# alb32r003x register map
Vendor: ALB; Series: ALB RT SoC
CPU: ALB XF, little endian
Registers are 32-bit, access not given, reset 0x0 unless marked. A register's access mark holds for its fields unless they carry their own. Offsets are from the block's base; [hi:lo] are bit positions; {n}, {i} and the like mark numbered series.

## ADCA
Base 0x20800100
Same registers: ADCB 0x20800300, ADCC 0x20800500
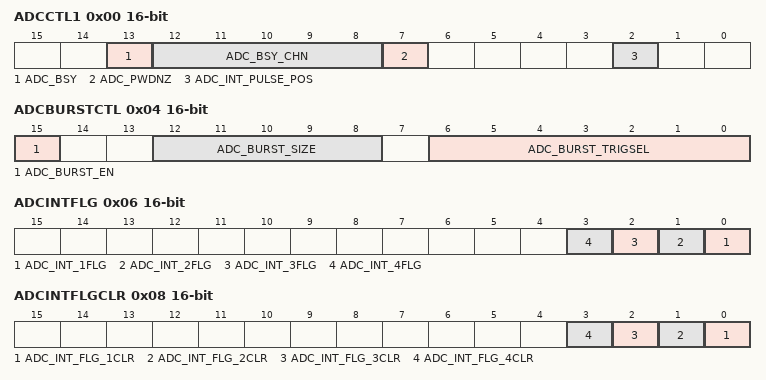
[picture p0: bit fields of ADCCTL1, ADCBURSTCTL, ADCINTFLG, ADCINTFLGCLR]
0x00 ADCCTL1 16-bit
  [13] ADC_BSY — ADC Busy. Set when ADC SOC is generated, cleared by hardware
  [12:8] ADC_BSY_CHN — ADC Busy Channel. Set when an ADC Start of Conversion (SOC) is
  [7] ADC_PWDNZ — ADC Power Down (active low). This bit controls the power up and
  [2] ADC_INT_PULSE_POS — ADC Interrupt Pulse Position.
0x02 ADCCTL2 16-bit
  [3:0] PRE_SCALE — ADC Clock Prescaler.
0x04 ADCBURSTCTL 16-bit
  [15] ADC_BURST_EN — SOC Burst Mode Enable. This bit enables the SOC Burst Mode of
  [12:8] ADC_BURST_SIZE — SOC Burst Size Select. This bit field determines how many SOCs
  [6:0] ADC_BURST_TRIGSEL — SOC Burst Trigger Source Select. Configures which trigger will start
0x06 ADCINTFLG 16-bit
  [n-1] ADC_INT_{n}FLG (n=1..4) — ADC Interrupt {n} Flag. Reading these flags indicates if the associated
0x08 ADCINTFLGCLR 16-bit
  [n-1] ADC_INT_FLG_{n}CLR (n=1..4) — ADC Interrupt {n} Flag Clear. Reads return 0.
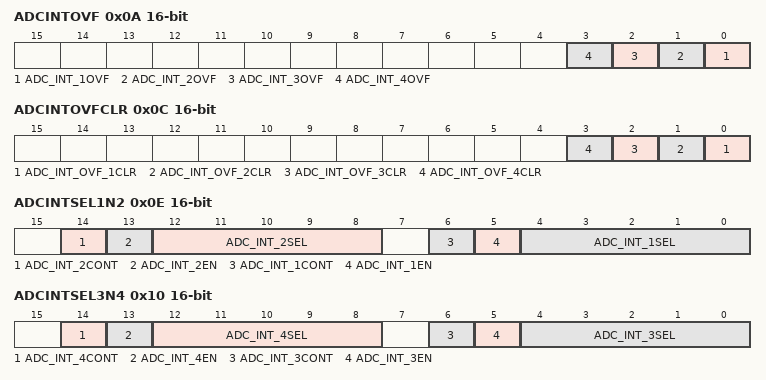
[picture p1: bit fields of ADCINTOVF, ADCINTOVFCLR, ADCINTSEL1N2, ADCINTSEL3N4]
0x0A ADCINTOVF 16-bit
  [n-1] ADC_INT_{n}OVF (n=1..4) — ADC Interrupt {n} Overflow Flags
0x0C ADCINTOVFCLR 16-bit
  [n-1] ADC_INT_OVF_{n}CLR (n=1..4) — ADC Interrupt {n} Overflow Clear Bits
0x0E ADCINTSEL1N2 16-bit
  [14] ADC_INT_2CONT — ADCINT2 Continue to Interrupt Mode
  [13] ADC_INT_2EN — ADCINT2 Interrupt Enable
  [12:8] ADC_INT_2SEL — ADCINT2 EOC Source Select
  [6] ADC_INT_1CONT — ADCINT1 Continue to Interrupt Mode
  [5] ADC_INT_1EN — ADCINT1 Interrupt Enable
  [4:0] ADC_INT_1SEL — ADCINT1 EOC Source Select
0x10 ADCINTSEL3N4 16-bit
  [14] ADC_INT_4CONT — ADCINT4 Continue to Interrupt Mode
  [13] ADC_INT_4EN — ADCINT4 Interrupt Enable
  [12:8] ADC_INT_4SEL — ADCINT4 EOC Source Select
  [6] ADC_INT_3CONT — ADCINT3 Continue to Interrupt Mode
  [5] ADC_INT_3EN — ADCINT3 Interrupt Enable
  [4:0] ADC_INT_3SEL — ADCINT3 EOC Source Select
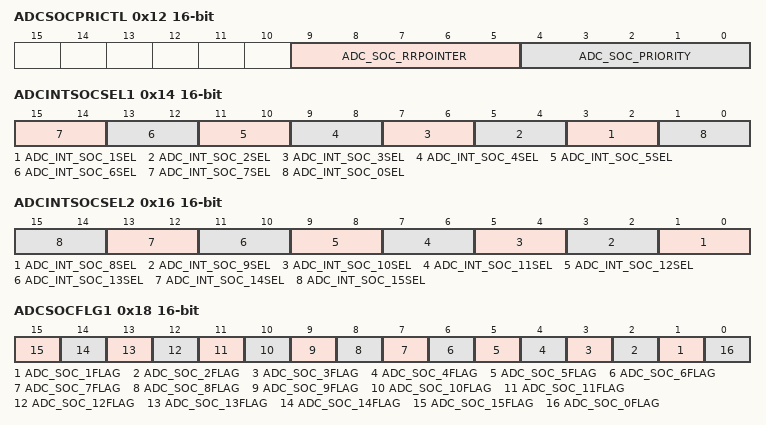
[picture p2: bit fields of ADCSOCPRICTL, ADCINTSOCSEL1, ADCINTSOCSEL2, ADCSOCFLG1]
0x12 ADCSOCPRICTL 16-bit
  [9:5] ADC_SOC_RRPOINTER — Round Robin Pointer. Holds the value of the last converted round
  [4:0] ADC_SOC_PRIORITY — SOC Priority
0x14 ADCINTSOCSEL1 16-bit
  [2n+1:2n] ADC_INT_SOC_{n}SEL (n=1..7) — SOC{n} ADC Interrupt Trigger Select. Selects which, if any, ADCINT
  [1:0] ADC_INT_SOC_0SEL — SOCO ADC Interrupt Trigger Select. Selects which, if any, ADCINT
0x16 ADCINTSOCSEL2 16-bit
  [2n-15:2n-16] ADC_INT_SOC_{n}SEL (n=8..15) — SOC{n} ADC Interrupt Trigger Select. Selects which, if any, ADCINT
0x18 ADCSOCFLG1 16-bit
  [n] ADC_SOC_{n}FLAG (n=1..15) — SOC{n} Start of Conversion Flag. Indicates the state of SOC{n}
  [0] ADC_SOC_0FLAG — SOCO Start of Conversion Flag. Indicates the state of SOCO
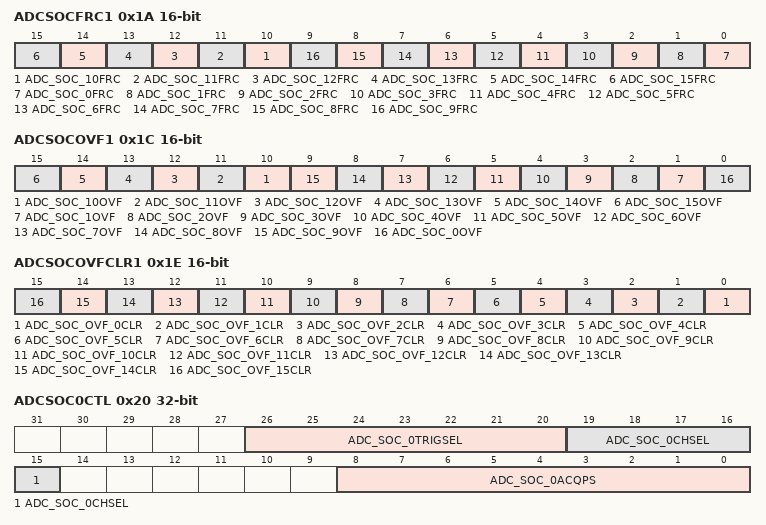
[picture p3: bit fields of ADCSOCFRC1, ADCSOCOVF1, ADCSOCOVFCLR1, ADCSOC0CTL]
0x1A ADCSOCFRC1 16-bit
  [n] ADC_SOC_{n}FRC (n=10..15) — SOC{n} Force Start of Conversion Bit. Writing a 1 will force to 1
  [n] ADC_SOC_{n}FRC (n=0..9) — SOC{n} Force Start of Conversion Bit. Writing a 1 will force to 1 the
0x1C ADCSOCOVF1 16-bit
  [n] ADC_SOC_{n}OVF (n=10..15) — SOC{n} Start of Conversion Overflow Flag. Indicates an SOC{n}
  [n] ADC_SOC_{n}OVF (n=1..9) — SOC{n} Start of Conversion Overflow Flag. Indicates an SOC{n} event
  [0] ADC_SOC_0OVF — SOC0 Start of Conversion Overflow Flag. Indicates an SOCo event
0x1E ADCSOCOVFCLR1 16-bit
  [n] ADC_SOC_OVF_{n}CLR (n=0..15) — SOC{n} Clear Start of Conversion Overflow Bit. Writing a 1 will clear
0x20 ADCSOC0CTL
  [26:20] ADC_SOC_0TRIGSEL — SOC0 Trigger Source Select. Along with the SOC0 field in the
  [19:15] ADC_SOC_0CHSEL — SOCO Channel Select. Selects the channel to be converted when
  [8:0] ADC_SOC_0ACQPS — SOCO Acquisition Prescale. Controls the sample and hold window
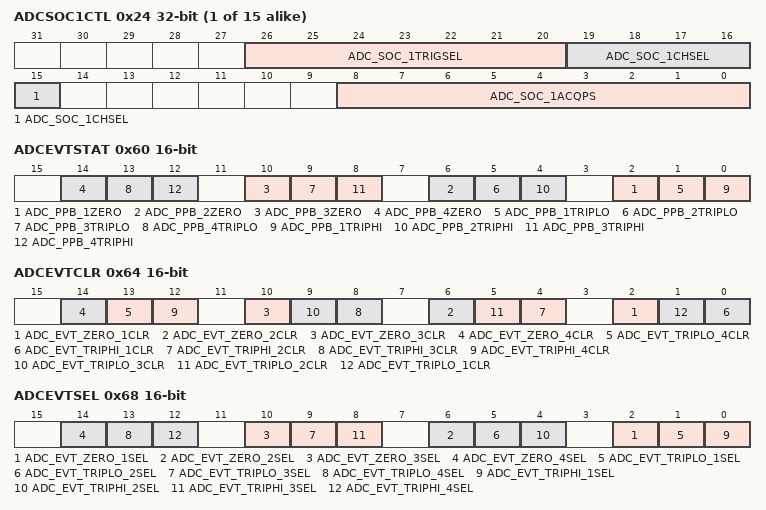
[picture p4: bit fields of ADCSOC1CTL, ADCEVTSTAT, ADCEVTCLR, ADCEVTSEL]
{0x20+4i} ADCSOC{i}CTL (i=1..15)
  [26:20] ADC_SOC_{i}TRIGSEL — SOC{i} Trigger Source Select. Along with the SOC{i} field in the
  [19:15] ADC_SOC_{i}CHSEL — SOC{i} Channel Select. Selects the channel to be converted when
  [8:0] ADC_SOC_{i}ACQPS — SOC{i} Acquisition Prescale. Controls the sample and hold window
0x60 ADCEVTSTAT 16-bit
  [4n-2] ADC_PPB_{n}ZERO (n=1..4) — Post Processing Block {n} Zero Crossing Flag. When set indicates the
  [4n-3] ADC_PPB_{n}TRIPLO (n=1..4) — Post Processing Block {n} Trip Low Flag. When set indicates a digital
  [4n-4] ADC_PPB_{n}TRIPHI (n=1..4) — Post Processing Block {n} Trip High Flag. When set indicates a digital
0x64 ADCEVTCLR 16-bit
  [4n-2] ADC_EVT_ZERO_{n}CLR (n=1..4) — Post Processing Block {n} Zero Crossing Clear. Clears the
  [13] ADC_EVT_TRIPLO_4CLR — Post Processing Block 4 Trip Low Clear. Clears the corresponding
  [4n-4] ADC_EVT_TRIPHI_{n}CLR (n=1..4) — Post Processing Block {n} Trip High Clear. Clears the corresponding
  [9] ADC_EVT_TRIPLO_3CLR — Post Processing Block 3 Trip Low Clear. Clears the corresponding
  [5] ADC_EVT_TRIPLO_2CLR — Post Processing Block 2 Trip Low Clear. Clears the corresponding
  [1] ADC_EVT_TRIPLO_1CLR — Post Processing Block 1 Trip Low Clear. Clears the correspondin g
0x68 ADCEVTSEL 16-bit
  [4n-2] ADC_EVT_ZERO_{n}SEL (n=1..4) — Post Processing Block {n} Zero Crossing Event Enable. Setting this
  [4n-3] ADC_EVT_TRIPLO_{n}SEL (n=1..4) — Post Processing Block {n} Trip Low Event Enable. Setting this bit
  [4n-4] ADC_EVT_TRIPHI_{n}SEL (n=1..4) — Post Processing Block {n} Trip High Event Enable. Setting this bit
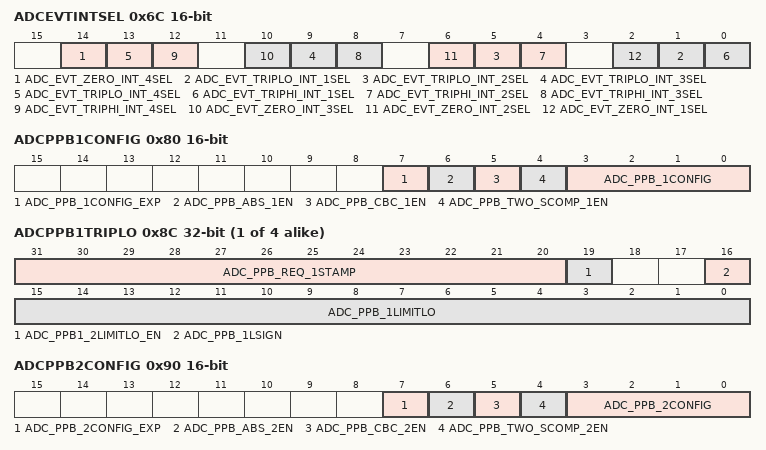
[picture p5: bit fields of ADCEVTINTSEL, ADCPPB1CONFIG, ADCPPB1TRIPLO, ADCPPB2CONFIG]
0x6C ADCEVTINTSEL 16-bit
  [14] ADC_EVT_ZERO_INT_4SEL — Post Processing Block 4 Zero Crossing Interrup t Enable. Setting this
  [4n-3] ADC_EVT_TRIPLO_INT_{n}SEL (n=1..4) — Post Processing Block {n} Trip Low Interrupt Enable. Setting this bit
  [4n-4] ADC_EVT_TRIPHI_INT_{n}SEL (n=1..4) — Post Processing Block {n} Trip High Interrupt Enable. Setting this bit
  [10] ADC_EVT_ZERO_INT_3SEL — Post Processing Block 3 Zero Crossing Interrup t Enable. Setting this
  [6] ADC_EVT_ZERO_INT_2SEL — Post Processing Block 2 Zero Crossing Interrupt Enable. Setting this
  [2] ADC_EVT_ZERO_INT_1SEL — Post Processing Block 1 Zero Crossing Interrupt Enable. Setting this
0x70 ADCOSDETECT 16-bit
  [2:0] ADC_OSDETECT — ADC Opens and Shorts Detect Configuration. This bit field defines
0x72 ADCCOUNTER 16-bit
  [11:0] ADC_COUNTER — ADC Free Running Counter Value. This bit field reflects the status of
0x76 ADCOFFTRIM 16-bit
  [7:0] ADC_OFFTRIM — ADC Offset Trim
0x80 ADCPPB1CONFIG 16-bit
  [7] ADC_PPB_1CONFIG_EXP
  [6] ADC_PPB_ABS_1EN — ADC Post Processing Block 1 Absolute Value Enable. When set
  [5] ADC_PPB_CBC_1EN — ADC Post Processing Block Cycle By Cycle Enable. When set,
  [4] ADC_PPB_TWO_SCOMP_1EN — ADC Post Processing Block 1 Two's Complement Enable. When set
  [3:0] ADC_PPB_1CONFIG — ADC Post Processing Block 1 Configuration. This bit field defines
{0x72+0x10*i} ADCPPB{i}STAMP 16-bit (i=1..4)
  [11:0] ADC_PPB_DLY_{i}STAMP — ADC Post Processing Block {i} Delay Time Stamp. When an SOC
{0x74+0x10*i} ADCPPB{i}OFFCAL 16-bit (i=1..4)
  [9:0] ADC_PPB_{i}OFFCAL — ADC Post Processing Block {i} Offset Correction. This bit field can
{0x76+0x10*i} ADCPPB{i}OFFREF 16-bit (i=1..4)
  [15:0] ADC_PPB_{i}OFFREF — ADC Post Processing Block {i} Offset Correction. This bit field
{0x78+0x10*i} ADCPPB{i}TRIPHI (i=1..4)
  [31:0] ADC_PPB_{i}LIMITHI — ADC Post Processing Block {i} Trip High Limit. This value sets the
{0x7C+0x10*i} ADCPPB{i}TRIPLO (i=1..4)
  [31:20] ADC_PPB_REQ_{i}STAMP — ADC Post Processing Block {i} Request Time Stamp. When a trigger
  [19] ADC_PPB{i}_2LIMITLO_EN — Extended Low Limit 2 Enable.
  [16] ADC_PPB_{i}LSIGN — Low Limit Sign Bit. This is the sign bit (17th bit) to the LIMITLO bit
  [15:0] ADC_PPB_{i}LIMITLO — ADC Post Processing Block {i} Trip Low Limit. This value sets
0x90 ADCPPB2CONFIG 16-bit
  [7] ADC_PPB_2CONFIG_EXP
  [6] ADC_PPB_ABS_2EN — ADC Post Processing Block 2 Absolute Value Enable. When set this bit enables absolute value calculation
  [5] ADC_PPB_CBC_2EN — ADC Post Processing Block Cycle By Cycle Enable. When set,
  [4] ADC_PPB_TWO_SCOMP_2EN — ADC Post Processing Block 2 Two's Complement Enable. When set
  [3:0] ADC_PPB_2CONFIG — ADC Post Processing Block 2 Configuration. This bit field defines
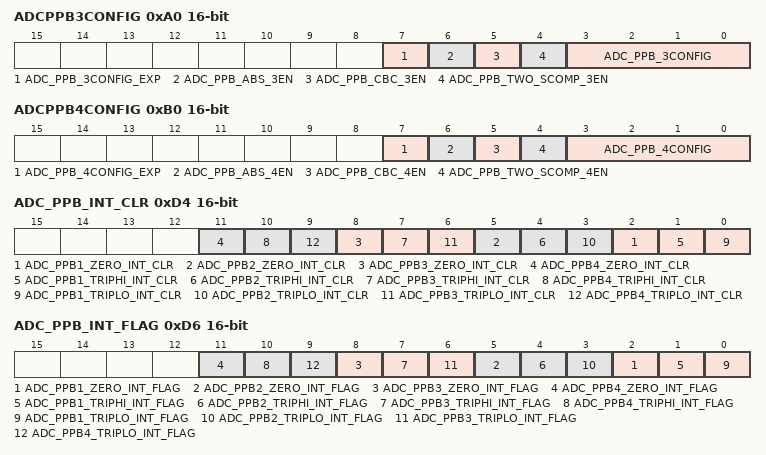
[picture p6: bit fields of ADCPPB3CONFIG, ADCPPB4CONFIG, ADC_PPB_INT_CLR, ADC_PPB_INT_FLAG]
0xA0 ADCPPB3CONFIG 16-bit
  [7] ADC_PPB_3CONFIG_EXP
  [6] ADC_PPB_ABS_3EN — ADC Post Processing Block 3 Absolute Value Enable. When set this bit enables absolute value calculation
  [5] ADC_PPB_CBC_3EN — ADC Post Processing Block Cycle By Cycle Enable. When set,
  [4] ADC_PPB_TWO_SCOMP_3EN — ADC Post Processing Block 3 Two's Complement Enable. When set
  [3:0] ADC_PPB_3CONFIG — ADC Post Processing Block 3 Configuration. This bit field defines
0xB0 ADCPPB4CONFIG 16-bit
  [7] ADC_PPB_4CONFIG_EXP
  [6] ADC_PPB_ABS_4EN — ADC Post Processing Block 4 Absolute Value Enable. When set
  [5] ADC_PPB_CBC_4EN — ADC Post Processing Block Cycle By Cycle Enable. When set,
  [4] ADC_PPB_TWO_SCOMP_4EN — ADC Post Processing Block 4 Two's Complement Enable. When set
  [3:0] ADC_PPB_4CONFIG — ADC Post Processing Block 4 Configuration. This bit field defines
0xD0 ADC_REGS_LOCK
  [31:0] ADC_REGS_LOCK — 锁定寄存器。对该寄存器写入lock值后，对受lock保护的所有寄存器不能写入。写其余值无影响;
0xD4 ADC_PPB_INT_CLR 16-bit
  [3n-1] ADC_PPB{n}_ZERO_INT_CLR (n=1..4), [3n-2] ADC_PPB{n}_TRIPHI_INT_CLR (n=1..4), [3n-3] ADC_PPB{n}_TRIPLO_INT_CLR (n=1..4)
0xD6 ADC_PPB_INT_FLAG 16-bit
  [3n-1] ADC_PPB{n}_ZERO_INT_FLAG (n=1..4), [3n-2] ADC_PPB{n}_TRIPHI_INT_FLAG (n=1..4), [3n-3] ADC_PPB{n}_TRIPLO_INT_FLAG (n=1..4)
0xD8 ADC_PPB_INT_MODE 16-bit
  [0] ADC_PPB_INT_MODE
0xDE ADCINTCYCLE 16-bit
  [15:0] ADC_INT_CYCLE — ADC Early Interrupt Generation Cycle Delay: Defines the delay from
{0xDC+4i} ADCINLTRIM{i} (i=1..3)
  [31:0] ADC_INL_TRIM_{32i-1}TO{32i-32} — ADC Linearity Trim Bits {32i-1}-{32i-32}.
